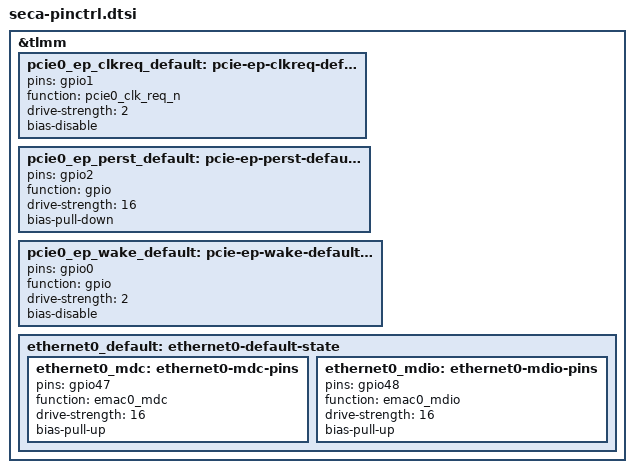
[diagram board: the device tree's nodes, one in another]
// SPDX-License-Identifier: BSD-3-Clause
/*
 * Copyright (c) Qualcomm Technologies, Inc. and/or its subsidiaries.
 */

&tlmm {
	pcie0_ep_clkreq_default: pcie-ep-clkreq-default-state {
		pins = "gpio1";
		function = "pcie0_clk_req_n";
		drive-strength = <2>;
		bias-disable;
	};

	pcie0_ep_perst_default: pcie-ep-perst-default-state {
		pins = "gpio2";
		function = "gpio";
		drive-strength = <16>;
		bias-pull-down;
	};

	pcie0_ep_wake_default: pcie-ep-wake-default-state {
		pins = "gpio0";
		function = "gpio";
		drive-strength = <2>;
		bias-disable;
	};

	ethernet0_default: ethernet0-default-state {
		ethernet0_mdc: ethernet0-mdc-pins {
			pins = "gpio47";
			function = "emac0_mdc";
			drive-strength = <16>;
			bias-pull-up;
		};

		ethernet0_mdio: ethernet0-mdio-pins {
			pins = "gpio48";
			function = "emac0_mdio";
			drive-strength = <16>;
			bias-pull-up;
		};
	};
};
